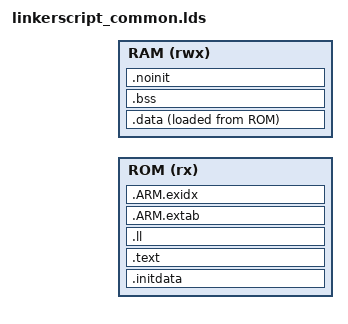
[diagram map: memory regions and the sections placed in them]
MEMORY
{
	ROM (rx) :  ORIGIN = TARGET_ROM_ORIGIN, LENGTH = TARGET_ROM_LEN
	RAM (rwx) : ORIGIN = TARGET_RAM_ORIGIN, LENGTH = TARGET_RAM_LEN
}

SECTIONS
{
	. = TARGET_ROM_ORIGIN;
	.initdata : ALIGN(4)
	{
		KEEP(*(.appinit));

		/*
		 * The preinit code, i.e. an array of pointers to initialisation
		 * functions to be performed before constructors.
		 */
		PROVIDE_HIDDEN (__preinit_array_start = .);

		/*
		 * Used to run the SystemInit() before anything else.
		 */
		KEEP(*(.preinit_array_sysinit .preinit_array_sysinit.*))

		/*
		 * Used for other platform inits.
		 */
		KEEP(*(.preinit_array_platform .preinit_array_platform.*))

		/*
		 * The application inits. If you need to enforce some order in
		 * execution, create new sections, as before.
		 */
		KEEP(*(.preinit_array .preinit_array.*))

		PROVIDE_HIDDEN (__preinit_array_end = .);

		. = ALIGN(4);

		/*
		 * The init code, i.e. an array of pointers to static constructors.
		 */
		PROVIDE_HIDDEN (__init_array_start = .);
		KEEP(*(SORT(.init_array.*)))
		KEEP(*(.init_array))
		PROVIDE_HIDDEN (__init_array_end = .);

		. = ALIGN(4);

		/*
		 * The fini code, i.e. an array of pointers to static destructors.
		 */
		PROVIDE_HIDDEN (__fini_array_start = .);
		KEEP(*(SORT(.fini_array.*)))
		KEEP(*(.fini_array))
		PROVIDE_HIDDEN (__fini_array_end = .);
	} > ROM

	.text : ALIGN(4)
	{
		*(.text .text.* .gnu.linkonce.t.*)
		*(.plt)
		*(.rodata .rodata.* .constdata .constdata.* .gnu.linkonce.r.*)
		*(vtable)					/* C++ virtual tables */
		KEEP(*(.eh_frame*))
		/*
		 * Stub sections generated by the linker, to glue together
		 * ARM and Thumb code. .glue_7 is used for ARM code calling
		 * Thumb code, and .glue_7t is used for Thumb code calling
		 * ARM code. Apparently always generated by the linker, for some
		 * architectures, so better leave them here.
		 */
		*(.glue_7)
		*(.glue_7t)
	} > ROM

	.ll : ALIGN(4)
	{
		PROVIDE_HIDDEN (__ll_entry_start = .);
		KEEP( *(SORT(.ll_entry_cmdlist*)) );
		PROVIDE_HIDDEN (__ll_entry_end = .);
	} > ROM

	/* ARM magic sections */
	.ARM.extab : ALIGN(4)
	{
		*(.ARM.extab* .gnu.linkonce.armextab.*)
	} > ROM

	. = ALIGN(4);
	__exidx_start = .;
	.ARM.exidx : ALIGN(4)
	{
		*(.ARM.exidx* .gnu.linkonce.armexidx.*)
	} > ROM
	__exidx_end = .;

	.data : ALIGN(4)
	{
		PROVIDE_HIDDEN (__data_load = LOADADDR(.data));
		PROVIDE_HIDDEN (__data_start = .);
		*(.data_begin .data_begin.*)
		*(.got.plt .got)
		*(.shdata)
		*(.data .data.* .gnu.linkonce.d.*)
		*(.data_end .data_end.*)
		PROVIDE_HIDDEN (__data_end = .);
		. = ALIGN(4);
	} > RAM  AT > ROM

	.bss : ALIGN(4)
	{
		PROVIDE_HIDDEN (__bss_start__ = .);
		*(.bss_begin .bss_begin.*)
		*(.shbss)
		*(.bss .bss.* .gnu.linkonce.b.*)
		*(COMMON)
		*(.bss_end .bss_end.*)
		PROVIDE_HIDDEN (__bss_end__ = .);
		. = ALIGN(4);
	} > RAM

	.noinit (NOLOAD) : ALIGN(4)
	{
		_noinit = .;
		*(.noinit .noinit.*)
		 . = ALIGN(4) ;
		_end_noinit = .;
	} > RAM
	/* After that there are only debugging sections. */

	/* This can remove the debugging information from the standard libraries */
	/*
	DISCARD :
	{
		libc.a ( * )
		libm.a ( * )
		libgcc.a ( * )
	}
	*/
	/* Stabs debugging sections.  */
	.stab          0 : { *(.stab) }
	.stabstr       0 : { *(.stabstr) }
	.stab.excl     0 : { *(.stab.excl) }
	.stab.exclstr  0 : { *(.stab.exclstr) }
	.stab.index    0 : { *(.stab.index) }
	.stab.indexstr 0 : { *(.stab.indexstr) }
	.comment       0 : { *(.comment) }
	/*
	 * DWARF debug sections.
	 * Symbols in the DWARF debugging sections are relative to the beginning
	 * of the section so we begin them at 0.
	 */
	/* DWARF 1 */
	.debug          0 : { *(.debug) }
	.line           0 : { *(.line) }
	/* GNU DWARF 1 extensions */
	.debug_srcinfo  0 : { *(.debug_srcinfo) }
	.debug_sfnames  0 : { *(.debug_sfnames) }
	/* DWARF 1.1 and DWARF 2 */
	.debug_aranges  0 : { *(.debug_aranges) }
	.debug_pubnames 0 : { *(.debug_pubnames) }
	/* DWARF 2 */
	.debug_info     0 : { *(.debug_info .gnu.linkonce.wi.*) }
	.debug_abbrev   0 : { *(.debug_abbrev) }
	.debug_line     0 : { *(.debug_line) }
	.debug_frame    0 : { *(.debug_frame) }
	.debug_str      0 : { *(.debug_str) }
	.debug_loc      0 : { *(.debug_loc) }
	.debug_macinfo  0 : { *(.debug_macinfo) }
	/* SGI/MIPS DWARF 2 extensions */
	.debug_weaknames 0 : { *(.debug_weaknames) }
	.debug_funcnames 0 : { *(.debug_funcnames) }
	.debug_typenames 0 : { *(.debug_typenames) }
	.debug_varnames  0 : { *(.debug_varnames) }
}
